# core register map
Vendor: litex
Litex SoC 2023-07-09 21:06:09
Registers are 32-bit, read-write, reset 0x0 unless marked. A register's access mark holds for its fields unless they carry their own. Offsets are from the block's base; lines under a group give offsets from that group; [hi:lo] are bit positions; {n}, {i} and the like mark numbered series; 'fields as' and 'values as' point back to an identical list; <NAME> marks a mode.

## Memory map
0xE0000000 D11CTIME size 0x8
0xE0001000 SUSRES size 0x2C
0xE0002000 COREUSER size 0x28
0xE0003000 CSRTEST size 0x8
0xE0004000 IRQARRAY0 size 0x10
0xE0005000 IRQARRAY1 size 0x10
{0xDFFFC000+0x1000*n} IRQARRAY{n} size 0x10 (n=10..19)
{0xE000E000+0x1000*n} IRQARRAY{n} size 0x10 (n=2..9)
0xE0018000 MAILBOX size 0x20
0xE0019000 MB_CLIENT size 0x20
0xE001A000 RESETVALUE size 0x4
0xE001B000 TICKTIMER size 0x24

## Interrupts
{n} irqarray{n} (IRQARRAY{n}) (n=0..19)
20 ticktimer (TICKTIMER)
21 susres (SUSRES)
22 mailbox (MAILBOX)
23 mb_client (MB_CLIENT)

## Further device data
memoryRegions:
  CSR baseAddress=0xE0000000 size=0x00040000
constants:
  CONFIG_CLOCK_FREQUENCY value=800000000
  CONFIG_CPU_HAS_INTERRUPT value=None
  CONFIG_CPU_RESET_ADDR value=1610612736
  CONFIG_CPU_HAS_DCACHE value=None
  CONFIG_CPU_HAS_ICACHE value=None
  CONFIG_CPU_TYPE_VEXRISCV_AXI value=None
  CONFIG_CPU_VARIANT_STANDARD value=None
  CONFIG_CPU_HUMAN_NAME value=VexRiscvAxi4
  CONFIG_CPU_NOP value=nop
  CONFIG_CSR_DATA_WIDTH value=32
  CONFIG_CSR_ALIGNMENT value=32
  CONFIG_BUS_STANDARD value=AXI-LITE
  CONFIG_BUS_DATA_WIDTH value=32
  CONFIG_BUS_ADDRESS_WIDTH value=32
  CONFIG_BUS_BURSTING value=0
  IRQARRAY{n}_INTERRUPT value={n} (n=0..19)
  MAILBOX_INTERRUPT value=22
  MB_CLIENT_INTERRUPT value=23
  SUSRES_INTERRUPT value=21
  TICKTIMER_INTERRUPT value=20

## D11CTIME
Base 0xE0000000
0x00 CONTROL reset 0x61A80
  [31:0] count — Number of ACLK ticks before creating a heart beat
0x04 HEARTBEAT
  [0] beat — Set to `1` at the next `count` interval rollover since `clear` was set.

## SUSRES
Base 0xE0001000
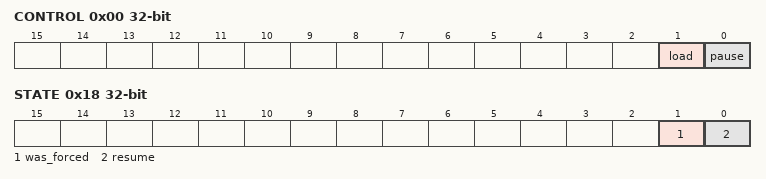
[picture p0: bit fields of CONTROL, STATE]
0x00 CONTROL
  [1] load — If paused, write a `1` to this bit to load a resume value to the timer. If not paused, this bit is ignored.
  [0] pause — Write a `1` to this field to request a pause to counting, 0 for free-run. Count pauses on the next tick quanta.
0x04 RESUME_TIME1 — Bits 32-63 of `SUSRES_RESUME_TIME`. Elapsed time to load. Loaded upon writing `1` to the load bit in the control register. This will immediately affect the msleep extension.
  [31:0] resume_time
0x08 RESUME_TIME0 — Bits 0-31 of `SUSRES_RESUME_TIME`.
  [31:0] resume_time
0x0C TIME1 — Bits 32-63 of `SUSRES_TIME`. Cycle-accurate mirror copy of time in systicks, from the TickTimer
  [31:0] time
0x10 TIME0 — Bits 0-31 of `SUSRES_TIME`.
  [31:0] time
0x14 STATUS
  [0] paused — When set, indicates that the counter has been paused
0x18 STATE
  [1] was_forced — Used by the bootloader to indicate to the kernel if the current resume was from a forced suspend (e.g. a timeout happened and a server may be unclean.
  [0] resume — Used to transfer the resume state information from the loader to Xous. If set, indicates we are on the resume half of a suspend/resume.
0x1C INTERRUPT
  [0] interrupt — Writing this causes an interrupt to fire. Used by Xous to initiate suspend/resume from an interrupt context.
0x20 EV_STATUS — This register contains the current raw level of the soft_int event trigger. Writes to this register have no effect.
  [0] soft_int — Level of the ``soft_int`` event
0x24 EV_PENDING — When a soft_int event occurs, the corresponding bit will be set in this register. To clear the Event, set the corresponding bit in this register.
  [0] soft_int — `1` if a `soft_int` event occurred. This Event is triggered on a **falling** edge.
0x28 EV_ENABLE — This register enables the corresponding soft_int events. Write a ``0`` to this register to disable individual events.
  [0] soft_int — Write a ``1`` to enable the ``soft_int`` Event
